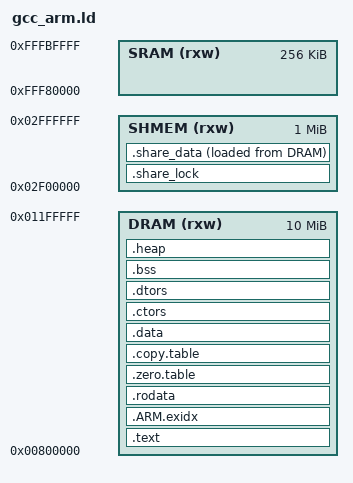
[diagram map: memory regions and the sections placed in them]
/* SPDX-License-Identifier: BSD-3-Clause */
/*
 * Copyright (c) 2022 Rockchip Electronics Co., Ltd.
 */
/* Automatically generated file; DO NOT EDIT. */
/* RT-Thread Project Configuration */
/* RT-Thread Kernel */
/* RT_USING_CORE_FREERTOS is not set */
/* RT_THREAD_PRIORITY_8 is not set */
/* RT_THREAD_PRIORITY_256 is not set */
/* RT_USING_TIMER_SOFT is not set */
/* RT_DEBUG_INIT_CONFIG is not set */
/* RT_DEBUG_USING_GPIO is not set */
/* RT_DEBUG_THREAD_CONFIG is not set */
/* RT_DEBUG_SCHEDULER_CONFIG is not set */
/* RT_DEBUG_IPC_CONFIG is not set */
/* RT_DEBUG_TIMER_CONFIG is not set */
/* RT_DEBUG_IRQ_CONFIG is not set */
/* RT_DEBUG_MEM_CONFIG is not set */
/* RT_DEBUG_SLAB_CONFIG is not set */
/* RT_DEBUG_MEMHEAP_CONFIG is not set */
/* RT_DEBUG_MODULE_CONFIG is not set */
/* Inter-Thread communication */
/* RT_USING_SIGNALS is not set */
/* Memory Management */
/* RT_USING_NOHEAP is not set */
/* RT_USING_SLAB is not set */
/* RT_USING_MEMHEAP_AS_HEAP is not set */
/* RT_USING_MEMTRACE is not set */
/* Kernel Device Object */
/* RT_USING_INTERRUPT_INFO is not set */
/* ARCH_CPU_STACK_GROWS_UPWARD is not set */
/* RT-Thread Components */
/* C++ features */
/* RT_USING_CPLUSPLUS is not set */
/* Command shell */
/* FINSH_ECHO_DISABLE_DEFAULT is not set */
/* FINSH_USING_AUTH is not set */
/* FINSH_USING_MSH_ONLY is not set */
/* Device virtual file system */
/* RT_USING_DFS_MNTTABLE is not set */
/* RT_USING_DFS_ELMFAT is not set */
/* RT_USING_DFS_ROMFS is not set */
/* RT_USING_DFS_RAMFS is not set */
/* RT_USING_DFS_UFFS is not set */
/* RT_USING_DFS_JFFS2 is not set */
/* RT_USING_LITTLEFS is not set */
/* Device Drivers */
/* RT_SERIAL_USING_DMA is not set */
/* RT_USING_CAN is not set */
/* RT_USING_HWTIMER is not set */
/* RT_USING_CPUTIME is not set */
/* RT_USING_I2C_BITOPS is not set */
/* RT_USING_MTD_NOR is not set */
/* RT_USING_MTD_NAND is not set */
/* RT_USING_MTD is not set */
/* RT_USING_PM is not set */
/* RT_USING_RTC is not set */
/* RT_USING_SDIO is not set */
/* RT_USING_SPI is not set */
/* RT_USING_WDT is not set */
/* RT_USING_AUDIO is not set */
/* RT_USING_SENSOR is not set */
/* RT_USING_TOUCH is not set */
/* Using WiFi */
/* RT_USING_WIFI is not set */
/* Using USB */
/* RT_USING_USB_HOST is not set */
/* RT_USING_USB_DEVICE is not set */
/* POSIX layer and C standard library */
/* RT_USING_PTHREADS is not set */
/* RT_USING_POSIX_MMAP is not set */
/* RT_USING_POSIX_TERMIOS is not set */
/* RT_USING_POSIX_AIO is not set */
/* RT_USING_MODULE is not set */
/* Network */
/* Socket abstraction layer */
/* RT_USING_SAL is not set */
/* light weight TCP/IP stack */
/* RT_USING_LWIP is not set */
/* Modbus master and slave stack */
/* RT_USING_MODBUS is not set */
/* AT commands */
/* RT_USING_AT is not set */
/* System */
/* RT_USING_LITTLEVGL2RTT is not set */
/* VBUS(Virtual Software BUS) */
/* RT_USING_VBUS is not set */
/* Utilities */
/* RT_USING_CMBACKTRACE is not set */
/* RT_USING_LOGTRACE is not set */
/* RT_USING_RYM is not set */
/* RT_USING_RZM is not set */
/* RT_USING_ULOG is not set */
/* RT_USING_UTEST is not set */
/* RT-Thread Benchmarks */
/* RT_USING_BENCHMARK is not set */
/* RT_USING_NET_HTTP is not set */
/* RT_USING_OTA is not set */
/* RT-Thread board config */
/* RT-Thread rockchip common drivers */
/* HAL_DBG_ON is not set */
/* RT_USING_SND_GLB_RST is not set */
/* RT_USING_RESET is not set */
/* RT_USING_CRU_DUMP is not set */
/* RT_USING_REGULATOR_DUMP is not set */
/* RT_USING_PROF_IRQ is not set */
/* RT_USING_PMIC is not set */
/* RT_USING_PWM_REGULATOR is not set */
/* RT_USING_CACHE is not set */
/* RT_USING_UNCACHE_HEAP is not set */
/* RT_USING_LARGE_HEAP is not set */
/* RT_USING_DTCM_HEAP is not set */
/* RT_USING_PSRAM_HEAP is not set */
/* Enable Fault Dump Hook */
/* RT_USING_SNOR is not set */
/* RT-Thread rockchip jpeg enc driver */
/* RT_USING_JPEG_ENC is not set */
/* RT-Thread rockchip pm drivers */
/* RT_USING_PM_DVFS is not set */
/* RT_USING_PM_REQ_PWR is not set */
/* RT_USING_PM_REQ_CLK is not set */
/* RT_USING_DVFS_DBG is not set */
/* RT_USING_PM_RUNTIME is not set */
/* RT_USING_PM_TIMER is not set */
/* RT-Thread rockchip mipi-dphy driver */
/* RT_USING_MIPI_DPHY is not set */
/* RT-Thread rockchip isp driver */
/* RT_USING_ISP is not set */
/* RT-Thread rockchip vcm driver */
/* RT_USING_VCM is not set */
/* RT-Thread rockchip vicap driver */
/* RT_USING_VICAP is not set */
/* RT-Thread rockchip camera driver */
/* RT_USING_CAMERA is not set */
/* RT-Thread rockchip vicap_lite driver */
/* RT_USING_VICAP_LITE is not set */
/* RT-Thread rockchip csi2host driver */
/* RT_USING_CSI2HOST is not set */
/* RT-Thread rockchip buffer_manage driver */
/* RT_USING_BUFFER_MANAGE is not set */
/* RT_USING_SENSOR_HUB is not set */
/* RT_USING_QPIPSRAM is not set */
/* RT-Thread rockchip coredump driver */
/* RT_USING_COREDUMP is not set */
/* RT_USING_SPINAND is not set */
/* Enable PSTORE */
/* RT_USING_PSTORE is not set */
/* RT-Thread rockchip RK3308 drivers */
/* RT_USING_DMA is not set */
/* Enable I2C */
/* Enable UART */
/* RT-Thread third party package */
/* PKG_CMSIS_RTOS2 is not set */
/* RT_USING_WLAN_WICED is not set */
/* RT_USING_NETUTILS is not set */
/* Bluetooth */
/* BT_ENABLED is not set */
/* examples bluetooth */
/* Bluetooth examlpes */
/* Example 'BT API TEST' Config */
/* BT_API_TEST is not set */
/* Example 'BT DISCOVERY' Config */
/* BT_DISCOVERY_EXAMPLES is not set */
/* Example 'A2DP SINK' Config */
/* A2DP_SINK_EXAMPLE is not set */
/* Example 'A2DP SOURCE' Config  */
/* A2DP_SOURCE_EXAMPLE is not set */
/* Example 'HFP CLIENT' Config */
/* HFP_CLIENT_EXAMPLE is not set */
/* RT_USING_CYPRESS is not set */
/* RT_USING_AUDIO_SERVER is not set */
MEMORY
{
    SRAM (rxw) : ORIGIN = 0xfff80000, LENGTH = 256K /* SYSTEM SRAM */
    DRAM (rxw) : ORIGIN = 0x00800000, LENGTH = 0x00a00000 /* DRAM */
    SHMEM (rxw) : ORIGIN = 0x02f00000, LENGTH = 0x00100000 /* shared memory for all cpu */
}
__SPINLOCK_MEM_SIZE = 0x100;
SECTIONS
{
    .text :
    {
        _stext = .;
        KEEP(*(.text.entrypoint)) /* The entry point */
        *(.vectors)
        *(.text) /* remaining code */
        *(.text.*) /* remaining code */
        *(.rodata) /* read-only data (constants) */
        *(.rodata*)
        *(.glue_7)
        *(.glue_7t)
        *(.gnu.linkonce.t*)
        *(COMMON)
        /* section information for finsh shell */
        . = ALIGN(16);
        __fsymtab_start = .;
        KEEP(*(FSymTab))
        __fsymtab_end = .;
        . = ALIGN(16);
        __vsymtab_start = .;
        KEEP(*(VSymTab))
        __vsymtab_end = .;
        . = ALIGN(16);
        /* section information for initial. */
        . = ALIGN(16);
        __rt_init_start = .;
        KEEP(*(SORT(.rti_fn*)))
        __rt_init_end = .;
        . = ALIGN(16);
        . = ALIGN(16);
        _etext = .;
    } > DRAM
    __exidx_start = .;
    .ARM.exidx :
    {
        *(.ARM.exidx* .gnu.linkonce.armexidx.*)
    } > DRAM
    __exidx_end = .;
    __rodata_start = .;
    .rodata :
    {
        *(.rodata) *(.rodata.*)
    } > DRAM
    __rodata_end = .;
    .zero.table :
    {
        . = ALIGN(4);
        __zero_table_start__ = .;
        LONG (ADDR(.bss))
        LONG (SIZEOF(.bss) / 4)
        LONG (ADDR(.share_lock))
        LONG (SIZEOF(.share_lock) / 4)
        __zero_table_end__ = .;
    } > DRAM
    .copy.table :
    {
        . = ALIGN(4);
        __copy_table_start__ = .;
       LONG (LOADADDR(.share_data))
       LONG (ADDR(.share_data))
       LONG (SIZEOF(.share_data) / 4)
        __copy_table_end__ = .;
    } > DRAM
    . = ALIGN(16);
    .data :
    {
        *(.data)
        *(.data.*)
        . = ALIGN(16);
        _gp = ABSOLUTE(.); /* Base of small data */
    } > DRAM
    . = ALIGN(16);
    .ctors :
    {
        PROVIDE(__ctors_start__ = .);
        KEEP(*(SORT(.ctors.*)))
        KEEP(*(.ctors))
        PROVIDE(__ctors_end__ = .);
    } > DRAM
    .dtors :
    {
        PROVIDE(__dtors_start__ = .);
        KEEP(*(SORT(.dtors.*)))
        KEEP(*(.dtors))
        PROVIDE(__dtors_end__ = .);
    } > DRAM
    .share_lock (NOLOAD) :
    {
        . = ALIGN(64);
        PROVIDE(__spinlock_mem_start__ = .);
        . += __SPINLOCK_MEM_SIZE;
        PROVIDE(__spinlock_mem_end__ = .);
        . = ALIGN(64);
    } > SHMEM
    .share_data :
    {
        . = ALIGN(64);
        PROVIDE(__share_data_start__ = .);
        KEEP(*(.share_data))
        PROVIDE(__share_data_end__ = .);
        . = ALIGN(64);
    } > SHMEM AT > DRAM
    . = ALIGN(16);
    .bss (NOLOAD) :
    {
        PROVIDE(__bss_start__ = .);
        *(.bss)
        *(.bss.*)
        *(.dynbss)
        *(COMMON)
        . = ALIGN(16);
        PROVIDE(__bss_end__ = .);
    } > DRAM
    .heap :
    {
        . = ALIGN(16);
        PROVIDE(__heap_begin = .);
        . = ORIGIN(DRAM) + LENGTH(DRAM);
        PROVIDE(__heap_end = .);
    } > DRAM
}
